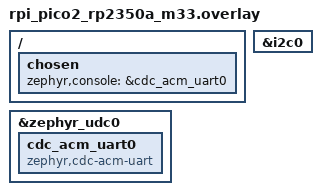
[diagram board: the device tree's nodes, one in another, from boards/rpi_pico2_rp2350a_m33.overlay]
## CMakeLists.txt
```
# == DO NOT EDIT THE FOLLOWING LINES for the Raspberry Pi Pico VS Code Extension to work ==
if(WIN32)
    set(USERHOME $ENV{USERPROFILE})
else()
    set(USERHOME $ENV{HOME})
endif()
set(sdkVersion 2.2.0)
set(toolchainVersion 14_2_Rel1)
set(picotoolVersion 2.2.0-a4)
set(picoVscode ${USERHOME}/.pico-sdk/cmake/pico-vscode.cmake)
if (EXISTS ${picoVscode})
    include(${picoVscode})
endif()
# ====================================================================================
set(PICO_BOARD pico CACHE STRING "Board type")

#pico-zephyr-project
#-------------------------------------------------------------------------------
# Zephyr Example Application
#
# Copyright (c) 2021 Nordic Semiconductor ASA
# SPDX-License-Identifier: Apache-2.0
#-------------------------------------------------------------------------------
# NOTE: Please do not remove the #pico-zephyr-project header, it is used by
# the Raspberry Pi Pico VS Code extension to identify the project type.
#-------------------------------------------------------------------------------

cmake_minimum_required(VERSION 3.20.0)

find_package(Zephyr REQUIRED HINTS $ENV{ZEPHYR_BASE})
project(moisture-humidity LANGUAGES C)

target_include_directories(app PRIVATE src/inc src/inc/humidity-sensor src/inc/light-sensor src/inc/moisture-sensor)

FILE(GLOB SRC_FILES
    "src/*.c"
    "src/inc/*.c"
    "src/inc/humidity-sensor/*.c"
    "src/inc/light-sensor/*.c"
    "src/inc/moisture-sensor/*.c"
)

target_sources(app PRIVATE ${SRC_FILES})
```

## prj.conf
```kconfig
CONFIG_SERIAL=y
CONFIG_CONSOLE=y
CONFIG_I2C=y
CONFIG_UART_CONSOLE=y
CONFIG_STDOUT_CONSOLE=y
CONFIG_UART_LINE_CTRL=y

CONFIG_USB_DEVICE_STACK_NEXT=y
CONFIG_CDC_ACM_SERIAL_INITIALIZE_AT_BOOT=y
CONFIG_CDC_ACM_SERIAL_PRODUCT_STRING="USBD console sample"
```

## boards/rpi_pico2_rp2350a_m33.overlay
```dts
/ {
    chosen {
		zephyr,console = &cdc_acm_uart0;
	};
};

&zephyr_udc0 {
	cdc_acm_uart0: cdc_acm_uart0 {
		compatible = "zephyr,cdc-acm-uart";
	};
};


&i2c0 {
    status = "okay";
};
```

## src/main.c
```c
#include "humidity_sensor.h"
#include "light_sensor.h"
#include "moisture_sensor.h"

static const struct device *i2c_bus;

int main(void) {
    i2c_bus = DEVICE_DT_GET(DT_NODELABEL(i2c0));

    init_humidity_sensor(i2c_bus);
    init_light_sensor(i2c_bus);
    init_moisture_sensor(i2c_bus);

    while (1) {
        uint16_t moisture;
        int l_whole, l_dec;
        int h_whole, h_dec;

        read_light_sensor(&l_whole, &l_dec);
        read_humidity_sensor(&h_whole, &h_dec);

        // int data = read_moisture_sensor(&moisture);
        read_moisture_sensor(&moisture);

        // if (data == 0) {
        printk("Moisture: %u\n", moisture);
        printk("Humidity: %d.%02d %%\n", h_whole, h_dec);
        printk("Lux: %d.%02d\n", l_whole, l_dec);
        // } else {
        // printf("Read failed: %d\n", data);
        // }

        k_msleep(3000);
    }
}
```
